# CH564 register map
Vendor: WCH Ltd.; File version: 1.0
CH564 View File
Registers are 8-bit, read-write, reset 0x0 unless marked. A register's access mark holds for its fields unless they carry their own. Offsets are from the block's base; lines under a group give offsets from that group; [hi:lo] are bit positions; {n}, {i} and the like mark numbered series; 'fields as' and 'values as' point back to an identical list; <NAME> marks a mode.

## Memory map
0x40028000 ETHERNET_MAC size 0xFF — Ethernet: media access control
0x40028100 ETHERNET_MMC size 0x400 — Ethernet: MAC management counters
0x40028700 ETHERNET_PTP size 0x400 — Ethernet: Precision time protocol
0x40029000 ETHERNET_DMA size 0x400 — Ethernet: DMA controller operation
0x40400000 SYS size 0x2000
0x40404000 USBHS_DEV size 0x400 — USB register
0x40404800 USBHS_HOST size 0x400 — USBHS Host mode functions' registers
0x40405000 USBHS_HSI size 0x400 — USBHS HSI calibration register
0x40408000 TIMER0 size 0x400 — TMR0 register
0x40408400 TIMER1 size 0x400 — TMR1 register
0x40408800 TIMER2 size 0x400 — TMR2 register
0x40408C00 TIMER3 size 0x400 — TMR3 register
0x40409000 UART2 size 0x800
0x40409800 UART3 size 0x800
0x4040A000 ADC size 0x1000
0x4040C000 SPI0 size 0x800
0x4040C800 SPI1 size 0x800
0x4040D000 UART0 size 0x800
0x4040D800 UART1 size 0x800
0x4040E000 USBPD size 0x1000 — USBPD configuration
0x4040F000 I2C1 size 0x1000 — Inter integrated circuit
0xE000E000 PFIC size 0x1100 — Programmable Fast Interrupt Controller

## Interrupts
16 I2C_EV (I2C1) — I2C event interrupt
17 I2C_ER (I2C1) — I2C1 error interrupt
18 ETH (ETHERNET_MAC) — Ethernet global interrupt
19 USBPD — USBPD global interrupt
20 TIM0 (TIMER0) — TIM0 Global interrupt
21 TIM1 (TIMER1) — TIM1 Global interrupt
22 TIM2 (TIMER2) — TIM2 Global interrupt
23 TIM3 (TIMER3) — TIM3 Global interrupt
24 SPI0 — SPI0 global interrupt
25 SPI1 — SPI1 global interrupt
26 UART0 — UART0 Global interrupt
27 UART1 — UART1 Global interrupt
28 PA (SYS) — PA external interrupt
29 PB (SYS) — PB external interrupt
30 PD (SYS) — PD external interrupt
31 ADC — ADC global interrupt
32 SLV (SYS) — SLV global interrupt
33 USBHS_HOST (USBHS_DEV)
34 USBHS_DEV — USBHS device
35 UART2 — UART2 Global interrupt
36 UART3 — UART3 Global interrupt
37 ETHWakeUP (ETHERNET_MAC) — Ethernet Wakeup through EXTI line interrupt
38 USBWakeup (USBHS_DEV)
39 USBPDWakeUP (USBPD) — USBPD_WKUP global interrupt

## TIMER0 — TMR0 register
Base 0x40408000
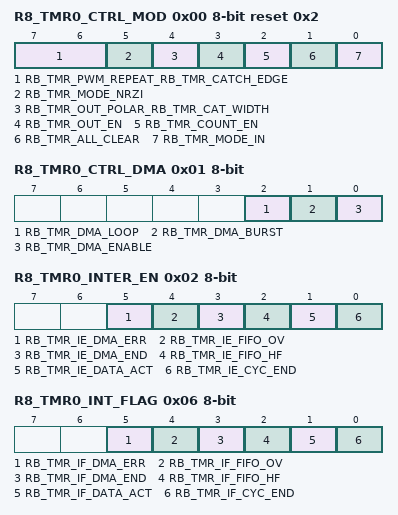
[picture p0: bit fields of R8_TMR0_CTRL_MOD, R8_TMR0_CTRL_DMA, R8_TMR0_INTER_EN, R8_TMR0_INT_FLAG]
0x00 R8_TMR0_CTRL_MOD reset 0x2 — TMR0 mode control
  [7:6] RB_TMR_PWM_REPEAT_RB_TMR_CATCH_EDGE — timer PWM repeat mode / timer capture edge mode
  [5] RB_TMR_MODE_NRZI — timer serial codec mode
  [4] RB_TMR_OUT_POLAR_RB_TMR_CAT_WIDTH — timer PWM output polarity / Capture pulse width
  [3] RB_TMR_OUT_EN — timer output enable
  [2] RB_TMR_COUNT_EN — timer count enable
  [1] RB_TMR_ALL_CLEAR — force clear timer FIFO and count
  [0] RB_TMR_MODE_IN — timer in mode
0x01 R8_TMR0_CTRL_DMA — TMR0 DMA control register
  [2] RB_TMR_DMA_LOOP — DMA address round-robin mode enabled
  [1] RB_TMR_DMA_BURST — DMA burst operation
  [0] RB_TMR_DMA_ENABLE — DMA function enable
0x02 R8_TMR0_INTER_EN — TMR0 interrupt enable
  [5] RB_TMR_IE_DMA_ERR — enable DMA error responde interrupt
  [4] RB_TMR_IE_FIFO_OV — enable interrupt for timer FIFO overflow
  [3] RB_TMR_IE_DMA_END — enable interrupt for timer DMA completion
  [2] RB_TMR_IE_FIFO_HF — enable interrupt for timer FIFO half (capture fifo >=4 or PWM fifo lower than3)
  [1] RB_TMR_IE_DATA_ACT — enable interrupt for timer capture input action or PWM trigger
  [0] RB_TMR_IE_CYC_END — enable interrupt for timer capture count timeout or PWM cycle end
0x06 R8_TMR0_INT_FLAG — TMR0 interrupt flag
  [5] RB_TMR_IF_DMA_ERR — DMA error responde flag
  [4] RB_TMR_IF_FIFO_OV — interrupt flag for timer FIFO overflow
  [3] RB_TMR_IF_DMA_END — interrupt flag for timer DMA completion
  [2] RB_TMR_IF_FIFO_HF — interrupt flag for timer FIFO half
  [1] RB_TMR_IF_DATA_ACT — interrupt flag for timer capture input action or PWM trigger
  [0] RB_TMR_IF_CYC_END — interrupt flag for timer capture count timeout or PWM cycle end
0x07 R8_TMR0_FIFO_COUNT ro — TMR0 FIFO count status
  [7:0] TMR0_FIFO_COUNT
0x08 R32_TMR0_COUNT 32-bit ro — TMR0 current count
  [27:0] TMR0_COUNT
0x0C R32_TMR0_CNT_END 32-bit — TMR0 end count value, only low 28 bit
  [27:0] TMR0_CNT_END — The number of timer ticks in timer mode
0x10 R32_TMR0_FIFO 32-bit read-only/write-only — TMR0 FIFO register, only low 28 bit
  [27:0] TMR0_FIFO — TMR0 FIFO current count
0x14 R32_TMR0_DMA_NOW 32-bit ro — DMA current buffer address register
  [17:0] TMR0_DMA_NOW — DMA current buffer address
0x18 R32_TMR0_DMA_BEG 32-bit — DMA start buffer address register
  [17:0] TMR0_DMA_BEG — DMA start buffer address
0x1C R32_TMR0_DMA_END 32-bit — DMA end buffer address register
  [17:0] TMR0_DMA_END — DMA end buffer address
